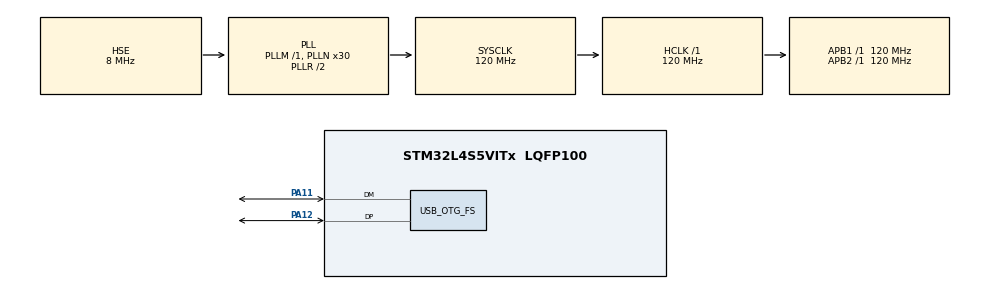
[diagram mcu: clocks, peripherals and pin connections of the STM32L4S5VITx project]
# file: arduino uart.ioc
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Mcu.Family=STM32L4
Mcu.Name=STM32L4S5VITx
Mcu.Package=LQFP100
NVIC.OTG_FS_IRQn=true\:0\:0\:false\:false\:true\:false\:true
NVIC.PriorityGroup=NVIC_PRIORITYGROUP_4
NVIC.TIM1_UP_TIM16_IRQn=true\:15\:0\:false\:false\:true\:false\:true
NVIC.TimeBase=TIM1_UP_TIM16_IRQn
NVIC.TimeBaseIP=TIM1
PA0.Mode=SYS_WakeUp0
PA0.Signal=SYS_WKUP1
PA11.Mode=Device_Only
PA11.Signal=USB_OTG_FS_DM
PA12.Mode=Device_Only
PA12.Signal=USB_OTG_FS_DP
PA13\ (JTMS/SWDIO).Mode=Serial_Wire
PA13\ (JTMS/SWDIO).Signal=SYS_JTMS-SWDIO
PA14\ (JTCK/SWCLK).Mode=Serial_Wire
PA14\ (JTCK/SWCLK).Signal=SYS_JTCK-SWCLK
PH0-OSC_IN\ (PH0).Mode=HSE-External-Oscillator
PH0-OSC_IN\ (PH0).Signal=RCC_OSC_IN
PH1-OSC_OUT\ (PH1).Mode=HSE-External-Oscillator
PH1-OSC_OUT\ (PH1).Signal=RCC_OSC_OUT
ProjectManager.HeapSize=0x200
ProjectManager.StackSize=0x400
ProjectManager.TargetToolchain=STM32CubeIDE
RCC.ADCFreq_Value=48000000
RCC.AHBFreq_Value=120000000
RCC.APB1Freq_Value=120000000
RCC.APB1TimFreq_Value=120000000
RCC.APB2Freq_Value=120000000
RCC.APB2TimFreq_Value=120000000
RCC.CortexFreq_Value=120000000
RCC.HCLKFreq_Value=120000000
RCC.HSE_VALUE=8000000
RCC.HSI48_VALUE=48000000
RCC.HSI_VALUE=16000000
RCC.LSE_VALUE=32768
RCC.MSI_VALUE=4000000
RCC.PLLN=30
RCC.PLLSAI1N=12
RCC.PLLSourceVirtual=RCC_PLLSOURCE_HSE
RCC.SYSCLKFreq_VALUE=120000000
RCC.SYSCLKSource=RCC_SYSCLKSOURCE_PLLCLK
RCC.USBFreq_Value=48000000
RCC.VCOOutputFreq_Value=240000000
USB_DEVICE.CLASS_NAME_FS=CDC
USB_DEVICE.VirtualMode=Cdc
USB_DEVICE.VirtualModeFS=Cdc_FS
USB_OTG_FS.VirtualMode=Device_Only
VP_SYS_VS_tim1.Mode=TIM1
VP_USB_DEVICE_VS_USB_DEVICE_CDC_FS.Mode=CDC_FS
board=custom

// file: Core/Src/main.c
/* USER CODE BEGIN Header */
/**
  ******************************************************************************
  * @file           : main.c
  * @brief          : Main program body
  ******************************************************************************
  * @attention
  *
  * Copyright (c) 2022 STMicroelectronics.
  * All rights reserved.
  *
  * This software is licensed under terms that can be found in the LICENSE file
  * in the root directory of this software component.
  * If no LICENSE file comes with this software, it is provided AS-IS.
  *
  ******************************************************************************
  */
/* USER CODE END Header */
#include "main.h"
#include "usb_device.h"
#include "gpio.h"

/* USER CODE BEGIN Includes */
#include "usbd_cdc_if.h"
/* USER CODE END Includes */

void SystemClock_Config(void);

int main(void)
{

  /* MCU Configuration--------------------------------------------------------*/

  /* Reset of all peripherals, Initializes the Flash interface and the Systick. */
  HAL_Init();

  /* Configure the system clock */
  SystemClock_Config();

  /* Initialize all configured peripherals */
  MX_GPIO_Init();
  MX_USB_DEVICE_Init();
  /* USER CODE BEGIN 2 */
  uint8_t text[] = "Hello World!\n\r";
  /* USER CODE END 2 */

  /* Infinite loop */
  /* USER CODE BEGIN WHILE */
  while (1)
  {
	  CDC_Transmit_FS(text, sizeof(text));
	  HAL_Delay(500);
    /* USER CODE END WHILE */

  }
}

void SystemClock_Config(void)
{
  RCC_OscInitTypeDef RCC_OscInitStruct = {0};
  RCC_ClkInitTypeDef RCC_ClkInitStruct = {0};

  /** Configure the main internal regulator output voltage
  */
  if (HAL_PWREx_ControlVoltageScaling(PWR_REGULATOR_VOLTAGE_SCALE1_BOOST) != HAL_OK)
  {
    Error_Handler();
  }
  /** Initializes the RCC Oscillators according to the specified parameters
  * in the RCC_OscInitTypeDef structure.
  */
  RCC_OscInitStruct.OscillatorType = RCC_OSCILLATORTYPE_HSE;
  RCC_OscInitStruct.HSEState = RCC_HSE_ON;
  RCC_OscInitStruct.PLL.PLLState = RCC_PLL_ON;
  RCC_OscInitStruct.PLL.PLLSource = RCC_PLLSOURCE_HSE;
  RCC_OscInitStruct.PLL.PLLM = 1;
  RCC_OscInitStruct.PLL.PLLN = 30;
  RCC_OscInitStruct.PLL.PLLP = RCC_PLLP_DIV2;
  RCC_OscInitStruct.PLL.PLLQ = RCC_PLLQ_DIV2;
  RCC_OscInitStruct.PLL.PLLR = RCC_PLLR_DIV2;
  if (HAL_RCC_OscConfig(&RCC_OscInitStruct) != HAL_OK)
  {
    Error_Handler();
  }
  /** Initializes the CPU, AHB and APB buses clocks
  */
  RCC_ClkInitStruct.ClockType = RCC_CLOCKTYPE_HCLK|RCC_CLOCKTYPE_SYSCLK
                              |RCC_CLOCKTYPE_PCLK1|RCC_CLOCKTYPE_PCLK2;
  RCC_ClkInitStruct.SYSCLKSource = RCC_SYSCLKSOURCE_PLLCLK;
  RCC_ClkInitStruct.AHBCLKDivider = RCC_SYSCLK_DIV1;
  RCC_ClkInitStruct.APB1CLKDivider = RCC_HCLK_DIV1;
  RCC_ClkInitStruct.APB2CLKDivider = RCC_HCLK_DIV1;

  if (HAL_RCC_ClockConfig(&RCC_ClkInitStruct, FLASH_LATENCY_5) != HAL_OK)
  {
    Error_Handler();
  }
}

void HAL_TIM_PeriodElapsedCallback(TIM_HandleTypeDef *htim)
{
  if (htim->Instance == TIM1) {
    HAL_IncTick();
  }
}

void Error_Handler(void)
{
  __disable_irq();
  while (1)
  {
  }
}
